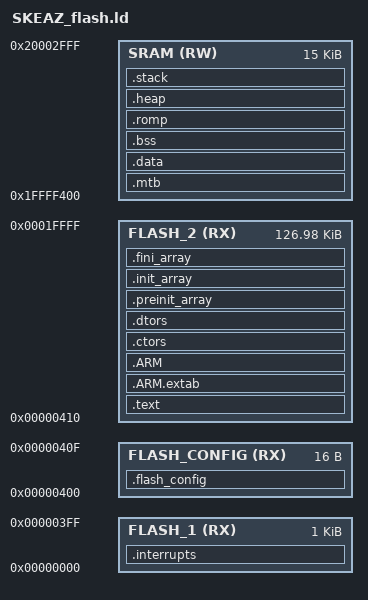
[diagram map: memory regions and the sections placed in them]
/*
** ###################################################################
**     Processors:          SKEAZ128MLD4
**                          SKEAZ128MLH4
**                          SKEAZ128MLH
**                          SKEAZ128MLK4
**                          SKEAZ128MLK
**
**     Compiler:            GNU C Compiler
**     Reference manual:    KEA128RM, Rev. 22, Jun 2014
**     Version:             rev. 1.4, 2015-07-24
**     Build:               b150730
**
**     Abstract:
**         Linker file for the GNU C Compiler
**
**     Copyright (c) 2015 Freescale Semiconductor, Inc.
**     All rights reserved.
**
**     Redistribution and use in source and binary forms, with or without modification,
**     are permitted provided that the following conditions are met:
**
**     o Redistributions of source code must retain the above copyright notice, this list
**       of conditions and the following disclaimer.
**
**     o Redistributions in binary form must reproduce the above copyright notice, this
**       list of conditions and the following disclaimer in the documentation and/or
**       other materials provided with the distribution.
**
**     o Neither the name of Freescale Semiconductor, Inc. nor the names of its
**       contributors may be used to endorse or promote products derived from this
**       software without specific prior written permission.
**
**     THIS SOFTWARE IS PROVIDED BY THE COPYRIGHT HOLDERS AND CONTRIBUTORS "AS IS" AND
**     ANY EXPRESS OR IMPLIED WARRANTIES, INCLUDING, BUT NOT LIMITED TO, THE IMPLIED
**     WARRANTIES OF MERCHANTABILITY AND FITNESS FOR A PARTICULAR PURPOSE ARE
**     DISCLAIMED. IN NO EVENT SHALL THE COPYRIGHT HOLDER OR CONTRIBUTORS BE LIABLE FOR
**     ANY DIRECT, INDIRECT, INCIDENTAL, SPECIAL, EXEMPLARY, OR CONSEQUENTIAL DAMAGES
**     (INCLUDING, BUT NOT LIMITED TO, PROCUREMENT OF SUBSTITUTE GOODS OR SERVICES;
**     LOSS OF USE, DATA, OR PROFITS; OR BUSINESS INTERRUPTION) HOWEVER CAUSED AND ON
**     ANY THEORY OF LIABILITY, WHETHER IN CONTRACT, STRICT LIABILITY, OR TORT
**     (INCLUDING NEGLIGENCE OR OTHERWISE) ARISING IN ANY WAY OUT OF THE USE OF THIS
**     SOFTWARE, EVEN IF ADVISED OF THE POSSIBILITY OF SUCH DAMAGE.
**
**     http:                 www.freescale.com
**     mail:                 support@freescale.com
**
** ###################################################################
*/

/* Entry Point */
ENTRY(Reset_Handler)

/*
To use "new" operator with EWL in C++ project the following symbol shall be defined
*/
/*EXTERN(_ZN10__cxxabiv119__terminate_handlerE)*/

/* Highest address of the user mode stack */
/* _estack = 0x20003000; */   /* end of SRAM */  
_estack = 0x1FFFF000 + 1K;
__SP_INIT = _estack;

HEAP_SIZE  = DEFINED(__heap_size__)  ? __heap_size__  : 0x00000000;
STACK_SIZE = DEFINED(__stack_size__) ? __stack_size__ : 0x00000400;

/* Specify the memory areas */
MEMORY
{
  FLASH_1          (RX)  : ORIGIN = 0x00000000, LENGTH = 0x00000400
  FLASH_CONFIG     (RX)  : ORIGIN = 0x00000400, LENGTH = 0x00000010
  FLASH_2          (RX)  : ORIGIN = 0x00000410, LENGTH = 0x0001FBF0
  /* SRAM             (RW)  : ORIGIN = 0x1FFFF000, LENGTH = 0x00004000 */
  SRAM			   (RW)  : ORIGIN = 0x1FFFF000 + 1K, LENGTH = 0x00004000 - 1K
}

/* Define output sections */
SECTIONS
{
  /* The startup code goes first into internal flash */
  .interrupts :
  {
    __VECTOR_TABLE = .;
    . = ALIGN(4);
    KEEP(*(.isr_vector))     /* Startup code */
    . = ALIGN(4);
  } > FLASH_1


  .flash_config :
  {
    . = ALIGN(4);
    KEEP(*(.FlashConfig))    /* Flash Configuration Field (FCF) */
    . = ALIGN(4);
  } > FLASH_CONFIG

  /* The program code and other data goes into internal flash */
  .text :
  {
    . = ALIGN(4);
    *(.text)                 /* .text sections (code) */
    *(.text*)                /* .text* sections (code) */
    *(.rodata)               /* .rodata sections (constants, strings, etc.) */
    *(.rodata*)              /* .rodata* sections (constants, strings, etc.) */
    *(.glue_7)               /* glue arm to thumb code */
    *(.glue_7t)              /* glue thumb to arm code */
    *(.eh_frame)
    KEEP (*(.init))
    KEEP (*(.fini))
    . = ALIGN(4);
  } > FLASH_2

  .ARM.extab :
  {
    *(.ARM.extab* .gnu.linkonce.armextab.*)
  } > FLASH_2

  .ARM :
  {
    __exidx_start = .;
    *(.ARM.exidx*)
    __exidx_end = .;
  } > FLASH_2

 .ctors :
  {
    __CTOR_LIST__ = .;
    /* gcc uses crtbegin.o to find the start of
       the constructors, so we make sure it is
       first.  Because this is a wildcard, it
       doesn't matter if the user does not
       actually link against crtbegin.o; the
       linker won't look for a file to match a
       wildcard.  The wildcard also means that it
       doesn't matter which directory crtbegin.o
       is in.  */
    KEEP (*crtbegin.o(.ctors))
    KEEP (*crtbegin?.o(.ctors))
    /* We don't want to include the .ctor section from
       from the crtend.o file until after the sorted ctors.
       The .ctor section from the crtend file contains the
       end of ctors marker and it must be last */
    KEEP (*(EXCLUDE_FILE(*crtend?.o *crtend.o) .ctors))
    KEEP (*(SORT(.ctors.*)))
    KEEP (*(.ctors))
    __CTOR_END__ = .;
  } > FLASH_2

  .dtors :
  {
    __DTOR_LIST__ = .;
    KEEP (*crtbegin.o(.dtors))
    KEEP (*crtbegin?.o(.dtors))
    KEEP (*(EXCLUDE_FILE(*crtend?.o *crtend.o) .dtors))
    KEEP (*(SORT(.dtors.*)))
    KEEP (*(.dtors))
    __DTOR_END__ = .;
  } > FLASH_2

  .preinit_array :
  {
    PROVIDE_HIDDEN (__preinit_array_start = .);
    KEEP (*(.preinit_array*))
    PROVIDE_HIDDEN (__preinit_array_end = .);
  } > FLASH_2

  .init_array :
  {
    PROVIDE_HIDDEN (__init_array_start = .);
    KEEP (*(SORT(.init_array.*)))
    KEEP (*(.init_array*))
    PROVIDE_HIDDEN (__init_array_end = .);
  } > FLASH_2

  .fini_array :
  {
    PROVIDE_HIDDEN (__fini_array_start = .);
    KEEP (*(SORT(.fini_array.*)))
    KEEP (*(.fini_array*))
    PROVIDE_HIDDEN (__fini_array_end = .);
  } > FLASH_2

  __etext = .;    /* define a global symbol at end of code */
  __DATA_ROM = .; /* Symbol is used by startup for data initialization */

  /* reserve MTB memory at the beginning of SRAM */
  .mtb : /* MTB buffer address as defined by the hardware */
  {
    . = ALIGN(8);
    _mtb_start = .;
    KEEP(*(.mtb_buf)) /* need to KEEP Micro Trace Buffer as not referenced by application */
    . = ALIGN(8);
    _mtb_end = .;
  } > SRAM

  .data : AT(__DATA_ROM)
  {
    . = ALIGN(4);
    __DATA_RAM = .;
    __data_start__ = .;      /* create a global symbol at data start */
    _sdata = .;        /* create a global symbol at data start */
    *(.data)                 /* .data sections */
    *(.data*)                /* .data* sections */
    KEEP(*(.jcr*))
    . = ALIGN(4);
    __data_end__ = .;        /* define a global symbol at data end */
    _edata = .;        /* define a global symbol at data end */
  } > SRAM

  /* Symbol is used by startup for data initialization */
  __DATA_END = __DATA_ROM + (__data_end__ - __data_start__);
   ___data_size = _edata - _sdata;

  /* Uninitialized data section */
  .bss :
  {
    /* This is used by the startup in order to initialize the .bss section */
    . = ALIGN(4);
    __START_BSS = .;
    __bss_start__ = .;
    *(.bss)
    *(.bss*)
    *(COMMON)
    . = ALIGN(4);
    __bss_end__ = .;
    __END_BSS = .;
  } > SRAM

  _romp_at = __DATA_ROM + SIZEOF(.data);
  .romp : AT(_romp_at)
  {
	__S_romp = _romp_at;
    LONG(__DATA_ROM);
    LONG(_sdata);
    LONG(___data_size);
    LONG(0);
    LONG(0);
    LONG(0);
  } > SRAM

  .heap :
  {
    . = ALIGN(8);
    __end__ = .;
    _end = .;
    PROVIDE(end = .);
    __HeapBase = .;
    . += HEAP_SIZE;
    __HeapLimit = .;
  } > SRAM

  .stack :
  {
    . = ALIGN(8);
    . += STACK_SIZE;
  } > SRAM

  __StackTop   = .;
  __StackLimit = __StackTop - STACK_SIZE;
  PROVIDE(__stack = __StackTop);

  .ARM.attributes 0 : { *(.ARM.attributes) }
}
